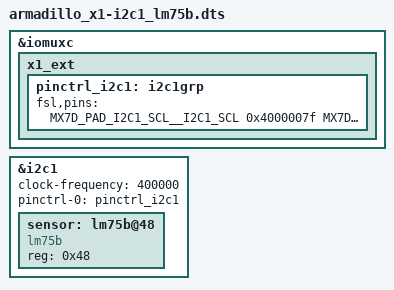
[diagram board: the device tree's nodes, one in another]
// SPDX-License-Identifier: GPL-2.0
/*
 * Copyright (C) 2024 Atmark Techno, Inc. All Rights Reserved.
 */

#include "armadillo_x1.dts"

/*
 * CON8_20: I2C1_SCL(have external pull-up)
 * CON8_21: I2C1_SDA(have external pull-up)
 */
&iomuxc {
	x1_ext {
		pinctrl_i2c1: i2c1grp {
			fsl,pins = <
				MX7D_PAD_I2C1_SCL__I2C1_SCL	0x4000007f
				MX7D_PAD_I2C1_SDA__I2C1_SDA	0x4000007f
			>;
		};
	};
};

&i2c1 {
	clock-frequency = <400000>;
	pinctrl-names = "default";
	pinctrl-0 = <&pinctrl_i2c1>;
	status = "okay";

	sensor: lm75b@48 {
		compatible = "lm75b";
		reg = <0x48>;
	};
};
